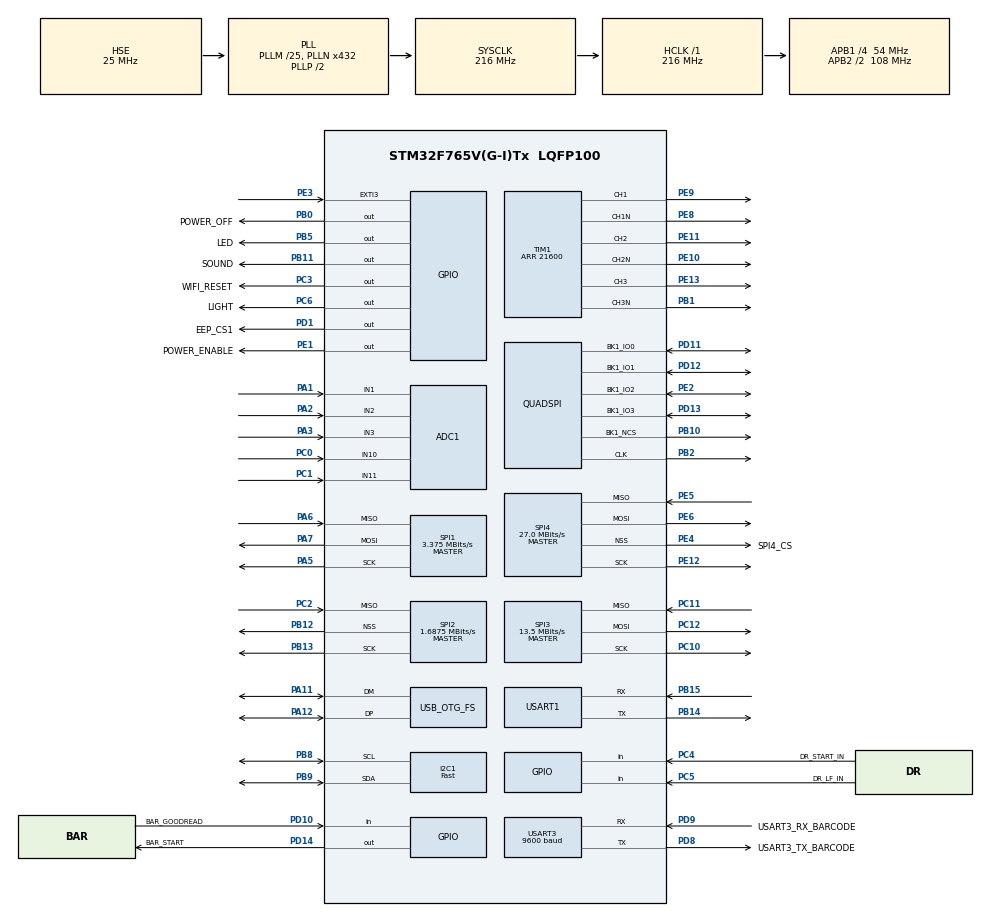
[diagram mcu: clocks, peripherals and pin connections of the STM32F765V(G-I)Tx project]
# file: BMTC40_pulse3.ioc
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ADC1.Channel-10\#ChannelRegularConversion=ADC_CHANNEL_10
ADC1.Channel-11\#ChannelRegularConversion=ADC_CHANNEL_11
ADC1.Channel-5\#ChannelRegularConversion=ADC_CHANNEL_1
ADC1.Channel-8\#ChannelRegularConversion=ADC_CHANNEL_2
ADC1.Channel-9\#ChannelRegularConversion=ADC_CHANNEL_3
ADC1.ClockPrescaler=ADC_CLOCK_SYNC_PCLK_DIV8
ADC1.ContinuousConvMode=DISABLE
ADC1.DMAContinuousRequests=ENABLE
ADC1.EOCSelection=ADC_EOC_SEQ_CONV
ADC1.NbrOfConversion=5
ADC1.NbrOfConversionFlag=1
ADC1.Rank-10\#ChannelRegularConversion=4
ADC1.Rank-11\#ChannelRegularConversion=5
ADC1.Rank-8\#ChannelRegularConversion=2
ADC1.Rank-9\#ChannelRegularConversion=3
ADC1.SamplingTime-10\#ChannelRegularConversion=ADC_SAMPLETIME_480CYCLES
ADC1.SamplingTime-11\#ChannelRegularConversion=ADC_SAMPLETIME_480CYCLES
ADC1.SamplingTime-5\#ChannelRegularConversion=ADC_SAMPLETIME_480CYCLES
ADC1.SamplingTime-8\#ChannelRegularConversion=ADC_SAMPLETIME_480CYCLES
ADC1.SamplingTime-9\#ChannelRegularConversion=ADC_SAMPLETIME_480CYCLES
ADC1.ScanConvMode=ADC_SCAN_ENABLE
ADC1.master=1
CORTEX_M7.ART_ACCELERATOR_ENABLE=0
CORTEX_M7.AccessPermission-Cortex_Memory_Protection_Unit_Region0_Settings=MPU_REGION_FULL_ACCESS
CORTEX_M7.BaseAddress-Cortex_Memory_Protection_Unit_Region0_Settings=0x20000000
CORTEX_M7.CPU_DCache=Enabled
CORTEX_M7.CPU_ICache=Enabled
CORTEX_M7.Enable-Cortex_Memory_Protection_Unit_Region0_Settings=MPU_REGION_ENABLE
CORTEX_M7.FlashInterface=AXI_Enabled
CORTEX_M7.IsBufferable-Cortex_Memory_Protection_Unit_Region0_Settings=MPU_ACCESS_NOT_BUFFERABLE
CORTEX_M7.IsShareable-Cortex_Memory_Protection_Unit_Region0_Settings=MPU_ACCESS_SHAREABLE
CORTEX_M7.MPU_Control=MPU_PRIVILEGED_DEFAULT
CORTEX_M7.PREFETCH_ENABLE=0
CORTEX_M7.Size-Cortex_Memory_Protection_Unit_Region0_Settings=MPU_REGION_SIZE_16KB
CORTEX_M7.TypeExtField-Cortex_Memory_Protection_Unit_Region0_Settings=MPU_TEX_LEVEL1
Dma.ADC1.2.Direction=DMA_PERIPH_TO_MEMORY
Dma.ADC1.2.FIFOMode=DMA_FIFOMODE_DISABLE
Dma.ADC1.2.Instance=DMA2_Stream4
Dma.ADC1.2.MemDataAlignment=DMA_MDATAALIGN_WORD
Dma.ADC1.2.MemInc=DMA_MINC_ENABLE
Dma.ADC1.2.Mode=DMA_NORMAL
Dma.ADC1.2.PeriphDataAlignment=DMA_PDATAALIGN_WORD
Dma.ADC1.2.PeriphInc=DMA_PINC_DISABLE
Dma.ADC1.2.Priority=DMA_PRIORITY_MEDIUM
Dma.I2C1_RX.0.Direction=DMA_PERIPH_TO_MEMORY
Dma.I2C1_RX.0.FIFOMode=DMA_FIFOMODE_DISABLE
Dma.I2C1_RX.0.Instance=DMA1_Stream0
Dma.I2C1_RX.0.MemDataAlignment=DMA_MDATAALIGN_BYTE
Dma.I2C1_RX.0.MemInc=DMA_MINC_ENABLE
Dma.I2C1_RX.0.Mode=DMA_NORMAL
Dma.I2C1_RX.0.PeriphDataAlignment=DMA_PDATAALIGN_BYTE
Dma.I2C1_RX.0.PeriphInc=DMA_PINC_DISABLE
Dma.I2C1_RX.0.Priority=DMA_PRIORITY_LOW
Dma.I2C1_TX.1.Direction=DMA_MEMORY_TO_PERIPH
Dma.I2C1_TX.1.FIFOMode=DMA_FIFOMODE_DISABLE
Dma.I2C1_TX.1.Instance=DMA1_Stream6
Dma.I2C1_TX.1.MemDataAlignment=DMA_MDATAALIGN_BYTE
Dma.I2C1_TX.1.MemInc=DMA_MINC_ENABLE
Dma.I2C1_TX.1.Mode=DMA_NORMAL
Dma.I2C1_TX.1.PeriphDataAlignment=DMA_PDATAALIGN_BYTE
Dma.I2C1_TX.1.PeriphInc=DMA_PINC_DISABLE
Dma.I2C1_TX.1.Priority=DMA_PRIORITY_LOW
Dma.Request0=I2C1_RX
Dma.Request1=I2C1_TX
Dma.Request10=SPI1_RX
Dma.Request11=SPI1_TX
Dma.Request2=ADC1
Dma.Request3=USART1_RX
Dma.Request4=USART1_TX
Dma.Request5=SPI4_RX
Dma.Request6=SPI4_TX
Dma.Request7=SPI2_RX
Dma.Request8=USART3_RX
Dma.Request9=USART3_TX
Dma.SPI1_RX.10.Direction=DMA_PERIPH_TO_MEMORY
Dma.SPI1_RX.10.FIFOMode=DMA_FIFOMODE_DISABLE
Dma.SPI1_RX.10.Instance=DMA2_Stream0
Dma.SPI1_RX.10.MemDataAlignment=DMA_MDATAALIGN_BYTE
Dma.SPI1_RX.10.MemInc=DMA_MINC_ENABLE
Dma.SPI1_RX.10.Mode=DMA_NORMAL
Dma.SPI1_RX.10.PeriphDataAlignment=DMA_PDATAALIGN_BYTE
Dma.SPI1_RX.10.PeriphInc=DMA_PINC_DISABLE
Dma.SPI1_RX.10.Priority=DMA_PRIORITY_VERY_HIGH
Dma.SPI1_TX.11.Direction=DMA_MEMORY_TO_PERIPH
Dma.SPI1_TX.11.FIFOMode=DMA_FIFOMODE_DISABLE
Dma.SPI1_TX.11.Instance=DMA2_Stream5
Dma.SPI1_TX.11.MemDataAlignment=DMA_MDATAALIGN_BYTE
Dma.SPI1_TX.11.MemInc=DMA_MINC_ENABLE
Dma.SPI1_TX.11.Mode=DMA_NORMAL
Dma.SPI1_TX.11.PeriphDataAlignment=DMA_PDATAALIGN_BYTE
Dma.SPI1_TX.11.PeriphInc=DMA_PINC_DISABLE
Dma.SPI1_TX.11.Priority=DMA_PRIORITY_VERY_HIGH
Dma.SPI2_RX.7.Direction=DMA_PERIPH_TO_MEMORY
Dma.SPI2_RX.7.FIFOMode=DMA_FIFOMODE_DISABLE
Dma.SPI2_RX.7.Instance=DMA1_Stream3
Dma.SPI2_RX.7.MemDataAlignment=DMA_MDATAALIGN_BYTE
Dma.SPI2_RX.7.MemInc=DMA_MINC_ENABLE
Dma.SPI2_RX.7.Mode=DMA_NORMAL
Dma.SPI2_RX.7.PeriphDataAlignment=DMA_PDATAALIGN_BYTE
Dma.SPI2_RX.7.PeriphInc=DMA_PINC_DISABLE
Dma.SPI2_RX.7.Priority=DMA_PRIORITY_HIGH
Dma.SPI4_RX.5.Direction=DMA_PERIPH_TO_MEMORY
Dma.SPI4_RX.5.FIFOMode=DMA_FIFOMODE_DISABLE
Dma.SPI4_RX.5.Instance=DMA2_Stream3
Dma.SPI4_RX.5.MemDataAlignment=DMA_MDATAALIGN_BYTE
Dma.SPI4_RX.5.MemInc=DMA_MINC_ENABLE
Dma.SPI4_RX.5.Mode=DMA_NORMAL
Dma.SPI4_RX.5.PeriphDataAlignment=DMA_PDATAALIGN_BYTE
Dma.SPI4_RX.5.PeriphInc=DMA_PINC_DISABLE
Dma.SPI4_RX.5.Priority=DMA_PRIORITY_LOW
Dma.SPI4_TX.6.Direction=DMA_MEMORY_TO_PERIPH
Dma.SPI4_TX.6.FIFOMode=DMA_FIFOMODE_DISABLE
Dma.SPI4_TX.6.Instance=DMA2_Stream1
Dma.SPI4_TX.6.MemDataAlignment=DMA_MDATAALIGN_BYTE
Dma.SPI4_TX.6.MemInc=DMA_MINC_ENABLE
Dma.SPI4_TX.6.Mode=DMA_NORMAL
Dma.SPI4_TX.6.PeriphDataAlignment=DMA_PDATAALIGN_BYTE
Dma.SPI4_TX.6.PeriphInc=DMA_PINC_DISABLE
Dma.SPI4_TX.6.Priority=DMA_PRIORITY_LOW
Dma.USART1_RX.3.Direction=DMA_PERIPH_TO_MEMORY
Dma.USART1_RX.3.FIFOMode=DMA_FIFOMODE_DISABLE
Dma.USART1_RX.3.Instance=DMA2_Stream2
Dma.USART1_RX.3.MemDataAlignment=DMA_MDATAALIGN_BYTE
Dma.USART1_RX.3.MemInc=DMA_MINC_ENABLE
Dma.USART1_RX.3.Mode=DMA_CIRCULAR
Dma.USART1_RX.3.PeriphDataAlignment=DMA_PDATAALIGN_BYTE
Dma.USART1_RX.3.PeriphInc=DMA_PINC_DISABLE
Dma.USART1_RX.3.Priority=DMA_PRIORITY_LOW
Dma.USART1_TX.4.Direction=DMA_MEMORY_TO_PERIPH
Dma.USART1_TX.4.FIFOMode=DMA_FIFOMODE_DISABLE
Dma.USART1_TX.4.Instance=DMA2_Stream7
Dma.USART1_TX.4.MemDataAlignment=DMA_MDATAALIGN_BYTE
Dma.USART1_TX.4.MemInc=DMA_MINC_ENABLE
Dma.USART1_TX.4.Mode=DMA_NORMAL
Dma.USART1_TX.4.PeriphDataAlignment=DMA_PDATAALIGN_BYTE
Dma.USART1_TX.4.PeriphInc=DMA_PINC_DISABLE
Dma.USART1_TX.4.Priority=DMA_PRIORITY_LOW
Dma.USART3_RX.8.Direction=DMA_PERIPH_TO_MEMORY
Dma.USART3_RX.8.FIFOMode=DMA_FIFOMODE_DISABLE
Dma.USART3_RX.8.Instance=DMA1_Stream1
Dma.USART3_RX.8.MemDataAlignment=DMA_MDATAALIGN_BYTE
Dma.USART3_RX.8.MemInc=DMA_MINC_ENABLE
Dma.USART3_RX.8.Mode=DMA_CIRCULAR
Dma.USART3_RX.8.PeriphDataAlignment=DMA_PDATAALIGN_BYTE
Dma.USART3_RX.8.PeriphInc=DMA_PINC_DISABLE
Dma.USART3_RX.8.Priority=DMA_PRIORITY_LOW
Dma.USART3_TX.9.Direction=DMA_MEMORY_TO_PERIPH
Dma.USART3_TX.9.FIFOMode=DMA_FIFOMODE_DISABLE
Dma.USART3_TX.9.Instance=DMA1_Stream4
Dma.USART3_TX.9.MemDataAlignment=DMA_MDATAALIGN_BYTE
Dma.USART3_TX.9.MemInc=DMA_MINC_ENABLE
Dma.USART3_TX.9.Mode=DMA_NORMAL
Dma.USART3_TX.9.PeriphDataAlignment=DMA_PDATAALIGN_BYTE
Dma.USART3_TX.9.PeriphInc=DMA_PINC_DISABLE
Dma.USART3_TX.9.Priority=DMA_PRIORITY_LOW
I2C1.GeneralCallMode=I2C_GENERALCALL_DISABLE
I2C1.I2C_Speed_Mode=I2C_Fast
I2C1.Timing=0x6000030D
IWDG.Prescaler=IWDG_PRESCALER_8
IWDG.Reload=2047
IWDG.Window=2047
Mcu.Family=STM32F7
Mcu.Name=STM32F765V(G-I)Tx
Mcu.Package=LQFP100
NVIC.DMA1_Stream0_IRQn=true\:4\:0\:true\:false\:true\:false\:true\:true
NVIC.DMA1_Stream1_IRQn=true\:4\:0\:true\:false\:true\:false\:true\:true
NVIC.DMA1_Stream3_IRQn=true\:2\:0\:false\:false\:true\:false\:true\:true
NVIC.DMA1_Stream4_IRQn=true\:4\:0\:true\:false\:true\:false\:true\:true
NVIC.DMA1_Stream6_IRQn=true\:4\:0\:true\:false\:true\:false\:true\:true
NVIC.DMA2_Stream0_IRQn=true\:0\:0\:true\:false\:true\:false\:true\:true
NVIC.DMA2_Stream1_IRQn=true\:4\:0\:true\:false\:true\:false\:true\:true
NVIC.DMA2_Stream2_IRQn=true\:4\:0\:true\:false\:true\:false\:true\:true
NVIC.DMA2_Stream3_IRQn=true\:4\:0\:true\:false\:true\:false\:true\:true
NVIC.DMA2_Stream4_IRQn=true\:4\:0\:false\:false\:true\:false\:true\:true
NVIC.DMA2_Stream5_IRQn=true\:0\:0\:false\:false\:true\:false\:true\:true
NVIC.DMA2_Stream7_IRQn=true\:4\:0\:true\:false\:true\:false\:true\:true
NVIC.EXTI3_IRQn=true\:4\:0\:true\:false\:true\:true\:true\:true
NVIC.I2C1_EV_IRQn=true\:4\:0\:true\:false\:true\:true\:true\:true
NVIC.OTG_FS_IRQn=true\:4\:0\:true\:false\:true\:true\:true\:true
NVIC.PriorityGroup=NVIC_PRIORITYGROUP_4
NVIC.QUADSPI_IRQn=true\:4\:0\:true\:false\:true\:true\:true\:true
NVIC.SPI2_IRQn=true\:2\:0\:true\:false\:true\:true\:true\:true
NVIC.TIM1_UP_TIM10_IRQn=true\:0\:0\:false\:false\:true\:true\:true\:true
NVIC.TIM8_TRG_COM_TIM14_IRQn=true\:1\:0\:true\:false\:true\:true\:true\:true
NVIC.TIM8_UP_TIM13_IRQn=true\:0\:0\:true\:false\:true\:true\:true\:true
NVIC.USART1_IRQn=true\:4\:0\:true\:false\:true\:true\:true\:true
PA0/WKUP.Mode=SYS_WakeUp0
PA0/WKUP.Signal=SYS_WKUP1
PA1.Signal=ADCx_IN1
PA11.GPIO_PuPd=GPIO_PULLDOWN
PA11.Mode=Device_Only
PA11.Signal=USB_OTG_FS_DM
PA12.GPIO_PuPd=GPIO_PULLDOWN
PA12.Mode=Device_Only
PA12.Signal=USB_OTG_FS_DP
PA13.Mode=JTAG_4_pins
PA13.Signal=SYS_JTMS-SWDIO
PA14.Mode=JTAG_4_pins
PA14.Signal=SYS_JTCK-SWCLK
PA15.Mode=JTAG_4_pins
PA15.Signal=SYS_JTDI
PA2.Signal=ADCx_IN2
PA3.Signal=ADCx_IN3
PA5.GPIO_PuPd=GPIO_PULLUP
PA5.Mode=Full_Duplex_Master
PA5.Signal=SPI1_SCK
PA6.Mode=Full_Duplex_Master
PA6.Signal=SPI1_MISO
PA7.Mode=Full_Duplex_Master
PA7.Signal=SPI1_MOSI
PB0.GPIO_Label=POWER_OFF
PB0.GPIO_PuPd=GPIO_PULLUP
PB0.PinState=GPIO_PIN_SET
PB0.Signal=GPIO_Output
PB1.GPIO_PuPd=GPIO_PULLDOWN
PB1.GPIO_Speed=GPIO_SPEED_FREQ_LOW
PB1.Mode=PWM Generation3 CH3 CH3N
PB1.Signal=TIM1_CH3N
PB10.GPIO_PuPd=GPIO_PULLDOWN
PB10.Mode=Single Bank 1
PB10.Signal=QUADSPI_BK1_NCS
PB11.GPIO_Label=SOUND
PB11.GPIO_PuPd=GPIO_PULLDOWN
PB11.Signal=GPIO_Output
PB12.GPIO_PuPd=GPIO_PULLUP
PB12.Mode=NSS_Signal_Hard_Output
PB12.Signal=SPI2_NSS
PB13.GPIO_PuPd=GPIO_PULLDOWN
PB13.Mode=RX_Only_Simplex_Unidirect_Master
PB13.Signal=SPI2_SCK
PB14.GPIO_PuPd=GPIO_PULLDOWN
PB14.Mode=Asynchronous
PB14.Signal=USART1_TX
PB15.GPIO_PuPd=GPIO_PULLDOWN
PB15.Mode=Asynchronous
PB15.Signal=USART1_RX
PB2.GPIO_PuPd=GPIO_PULLDOWN
PB2.Mode=Single Bank 1
PB2.Signal=QUADSPI_CLK
PB3.Mode=JTAG_4_pins
PB3.Signal=SYS_JTDO-SWO
PB5.GPIO_Label=LED
PB5.GPIO_PuPd=GPIO_PULLDOWN
PB5.Signal=GPIO_Output
PB8.GPIO_Pu=GPIO_PULLUP
PB8.Mode=I2C
PB8.Signal=I2C1_SCL
PB9.GPIO_Pu=GPIO_PULLUP
PB9.Mode=I2C
PB9.Signal=I2C1_SDA
PC0.Signal=ADCx_IN10
PC1.Signal=ADCx_IN11
PC10.GPIO_PuPd=GPIO_PULLDOWN
PC10.Mode=Full_Duplex_Master
PC10.Signal=SPI3_SCK
PC11.GPIO_PuPd=GPIO_PULLDOWN
PC11.Mode=Full_Duplex_Master
PC11.Signal=SPI3_MISO
PC12.GPIO_PuPd=GPIO_PULLDOWN
PC12.Mode=Full_Duplex_Master
PC12.Signal=SPI3_MOSI
PC14/OSC32_IN.Mode=LSE-External-Oscillator
PC14/OSC32_IN.Signal=RCC_OSC32_IN
PC15/OSC32_OUT.Mode=LSE-External-Oscillator
PC15/OSC32_OUT.Signal=RCC_OSC32_OUT
PC2.GPIO_PuPd=GPIO_PULLDOWN
PC2.Mode=RX_Only_Simplex_Unidirect_Master
PC2.Signal=SPI2_MISO
PC3.GPIO_Label=WIFI_RESET
PC3.GPIO_PuPd=GPIO_PULLDOWN
PC3.Signal=GPIO_Output
PC4.GPIO_Label=DR_START_IN
PC4.GPIO_PuPd=GPIO_PULLUP
PC4.Signal=GPIO_Input
PC5.GPIO_Label=DR_LF_IN
PC5.GPIO_PuPd=GPIO_PULLUP
PC5.Signal=GPIO_Input
PC6.GPIO_Label=LIGHT
PC6.GPIO_PuPd=GPIO_PULLDOWN
PC6.Signal=GPIO_Output
PD1.GPIO_Label=EEP_CS1
PD1.GPIO_ModeDefaultOutputPP=GPIO_MODE_OUTPUT_PP
PD1.GPIO_PuPd=GPIO_PULLUP
PD1.GPIO_Speed=GPIO_SPEED_FREQ_HIGH
PD1.PinState=GPIO_PIN_SET
PD1.Signal=GPIO_Output
PD10.GPIO_Label=BAR_GOODREAD
PD10.GPIO_PuPd=GPIO_PULLDOWN
PD10.Signal=GPIO_Input
PD11.GPIO_PuPd=GPIO_PULLDOWN
PD11.Mode=Single Bank 1
PD11.Signal=QUADSPI_BK1_IO0
PD12.GPIO_PuPd=GPIO_PULLDOWN
PD12.Mode=Single Bank 1
PD12.Signal=QUADSPI_BK1_IO1
PD13.GPIO_PuPd=GPIO_PULLDOWN
PD13.Mode=Single Bank 1
PD13.Signal=QUADSPI_BK1_IO3
PD14.GPIO_Label=BAR_START
PD14.GPIO_PuPd=GPIO_PULLDOWN
PD14.Signal=GPIO_Output
PD8.GPIO_Label=USART3_TX_BARCODE
PD8.GPIO_PuPd=GPIO_PULLDOWN
PD8.GPIO_Speed=GPIO_SPEED_FREQ_LOW
PD8.Mode=Asynchronous
PD8.Signal=USART3_TX
PD9.GPIO_Label=USART3_RX_BARCODE
PD9.GPIO_PuPd=GPIO_PULLDOWN
PD9.GPIO_Speed=GPIO_SPEED_FREQ_LOW
PD9.Mode=Asynchronous
PD9.Signal=USART3_RX
PE1.GPIO_Label=POWER_ENABLE
PE1.GPIO_PuPd=GPIO_PULLDOWN
PE1.PinState=GPIO_PIN_SET
PE1.Signal=GPIO_Output
PE10.GPIO_PuPd=GPIO_PULLDOWN
PE10.GPIO_Speed=GPIO_SPEED_FREQ_LOW
PE10.Mode=PWM Generation2 CH2 CH2N
PE10.Signal=TIM1_CH2N
PE11.GPIO_PuPd=GPIO_PULLDOWN
PE11.GPIO_Speed=GPIO_SPEED_FREQ_LOW
PE11.Signal=S_TIM1_CH2
PE12.GPIO_PuPd=GPIO_PULLDOWN
PE12.Mode=Full_Duplex_Master
PE12.Signal=SPI4_SCK
PE13.GPIO_PuPd=GPIO_PULLDOWN
PE13.GPIO_Speed=GPIO_SPEED_FREQ_LOW
PE13.Signal=S_TIM1_CH3
PE2.GPIO_PuPd=GPIO_PULLDOWN
PE2.Mode=Single Bank 1
PE2.Signal=QUADSPI_BK1_IO2
PE3.Signal=GPXTI3
PE4.GPIO_Label=SPI4_CS
PE4.Mode=NSS_Signal_Hard_Output
PE4.Signal=SPI4_NSS
PE5.GPIO_PuPd=GPIO_PULLDOWN
PE5.Mode=Full_Duplex_Master
PE5.Signal=SPI4_MISO
PE6.GPIO_PuPd=GPIO_PULLDOWN
PE6.Mode=Full_Duplex_Master
PE6.Signal=SPI4_MOSI
PE8.GPIO_PuPd=GPIO_PULLDOWN
PE8.GPIO_Speed=GPIO_SPEED_FREQ_LOW
PE8.Mode=PWM Generation1 CH1 CH1N
PE8.Signal=TIM1_CH1N
PE9.GPIO_PuPd=GPIO_PULLDOWN
PE9.GPIO_Speed=GPIO_SPEED_FREQ_LOW
PE9.Signal=S_TIM1_CH1
PH0/OSC_IN.Mode=HSE-External-Oscillator
PH0/OSC_IN.Signal=RCC_OSC_IN
PH1/OSC_OUT.Mode=HSE-External-Oscillator
PH1/OSC_OUT.Signal=RCC_OSC_OUT
ProjectManager.HeapSize=0x700
ProjectManager.StackSize=0x1000
ProjectManager.TargetToolchain=STM32CubeIDE
QUADSPI.ChipSelectHighTime=QSPI_CS_HIGH_TIME_5_CYCLE
QUADSPI.ClockPrescaler=2
QUADSPI.FlashSize=24 - 1
QUADSPI.SampleShifting=QSPI_SAMPLE_SHIFTING_HALFCYCLE
RCC.AHBFreq_Value=216000000
RCC.APB1CLKDivider=RCC_HCLK_DIV4
RCC.APB1Freq_Value=54000000
RCC.APB1TimFreq_Value=108000000
RCC.APB2CLKDivider=RCC_HCLK_DIV2
RCC.APB2Freq_Value=108000000
RCC.APB2TimFreq_Value=216000000
RCC.CortexFreq_Value=216000000
RCC.HCLKFreq_Value=216000000
RCC.HSE_VALUE=25000000
RCC.HSI_VALUE=16000000
RCC.PLLM=25
RCC.PLLN=432
RCC.PLLQ=9
RCC.RCC_MCO1Source=RCC_MCO1SOURCE_HSE
RCC.RTCClockSelection=RCC_RTCCLKSOURCE_LSE
RCC.SYSCLKFreq_VALUE=216000000
RCC.SYSCLKSource=RCC_SYSCLKSOURCE_PLLCLK
RCC.USBFreq_Value=48000000
RCC.VCOOutputFreq_Value=432000000
SH.ADCx_IN1.0=ADC1_IN1,IN1
SH.ADCx_IN10.0=ADC1_IN10,IN10
SH.ADCx_IN11.0=ADC1_IN11,IN11
SH.ADCx_IN2.0=ADC1_IN2,IN2
SH.ADCx_IN3.0=ADC1_IN3,IN3
SH.S_TIM1_CH1.0=TIM1_CH1,PWM Generation1 CH1 CH1N
SH.S_TIM1_CH2.0=TIM1_CH2,PWM Generation2 CH2 CH2N
SH.S_TIM1_CH3.0=TIM1_CH3,PWM Generation3 CH3 CH3N
SPI1.BaudRatePrescaler=SPI_BAUDRATEPRESCALER_32
SPI1.CLKPhase=SPI_PHASE_2EDGE
SPI1.CLKPolarity=SPI_POLARITY_HIGH
SPI1.CalculateBaudRate=3.375 MBits/s
SPI1.DataSize=SPI_DATASIZE_8BIT
SPI1.Direction=SPI_DIRECTION_2LINES
SPI1.Mode=SPI_MODE_MASTER
SPI1.VirtualType=VM_MASTER
SPI2.BaudRatePrescaler=SPI_BAUDRATEPRESCALER_32
SPI2.CalculateBaudRate=1.6875 MBits/s
SPI2.DataSize=SPI_DATASIZE_8BIT
SPI2.Direction=SPI_DIRECTION_2LINES_RXONLY
SPI2.Mode=SPI_MODE_MASTER
SPI2.NSSPMode=SPI_NSS_PULSE_DISABLE
SPI2.VirtualNSS=VM_NSSHARD
SPI2.VirtualType=VM_MASTER
SPI3.BaudRatePrescaler=SPI_BAUDRATEPRESCALER_4
SPI3.CalculateBaudRate=13.5 MBits/s
SPI3.DataSize=SPI_DATASIZE_8BIT
SPI3.Direction=SPI_DIRECTION_2LINES
SPI3.Mode=SPI_MODE_MASTER
SPI3.VirtualType=VM_MASTER
SPI4.BaudRatePrescaler=SPI_BAUDRATEPRESCALER_4
SPI4.CalculateBaudRate=27.0 MBits/s
SPI4.DataSize=SPI_DATASIZE_8BIT
SPI4.Direction=SPI_DIRECTION_2LINES
SPI4.Mode=SPI_MODE_MASTER
SPI4.VirtualNSS=VM_NSSHARD
SPI4.VirtualType=VM_MASTER
TIM1.AutoReloadPreload=TIM_AUTORELOAD_PRELOAD_DISABLE
TIM1.Channel-PWM\ Generation1\ CH1\ CH1N=TIM_CHANNEL_1
TIM1.Channel-PWM\ Generation2\ CH2\ CH2N=TIM_CHANNEL_2
TIM1.Channel-PWM\ Generation3\ CH3\ CH3N=TIM_CHANNEL_3
TIM1.CounterMode=TIM_COUNTERMODE_UP
TIM1.DeadTime=210
TIM1.OCFastMode_PWM-PWM\ Generation1\ CH1\ CH1N=TIM_OCFAST_ENABLE
TIM1.OCFastMode_PWM-PWM\ Generation2\ CH2\ CH2N=TIM_OCFAST_ENABLE
TIM1.OCFastMode_PWM-PWM\ Generation3\ CH3\ CH3N=TIM_OCFAST_ENABLE
TIM1.Period=21600
TIM1.RepetitionCounter=0
TIM13.AutoReloadPreload=TIM_AUTORELOAD_PRELOAD_ENABLE
TIM13.Period=10800
TIM14.AutoReloadPreload=TIM_AUTORELOAD_PRELOAD_ENABLE
TIM14.Period=10800/2
USART1.VirtualMode-Asynchronous=VM_ASYNC
USART3.BaudRate=9600
USART3.VirtualMode-Asynchronous=VM_ASYNC
USB_DEVICE.CLASS_NAME_FS=CDC
USB_DEVICE.MANUFACTURER_STRING-CDC_FS=HANTAS
USB_DEVICE.PRODUCT_STRING_CDC_FS=Virtual ComPort
USB_DEVICE.VirtualMode-CDC_FS=Cdc
USB_DEVICE.VirtualModeFS=Cdc_FS
USB_OTG_FS.VirtualMode=Device_Only
VP_IWDG_VS_IWDG.Mode=IWDG_Activate
VP_RTC_VS_RTC_Activate.Mode=RTC_Enabled
VP_RTC_VS_RTC_Calendar.Mode=RTC_Calendar
VP_TIM13_VS_ClockSourceINT.Mode=Enable_Timer
VP_TIM14_VS_ClockSourceINT.Mode=Enable_Timer
VP_USB_DEVICE_VS_USB_DEVICE_CDC_FS.Mode=CDC_FS
board=MDC_F765VG_BAT

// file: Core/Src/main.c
/* USER CODE BEGIN Header */
/**
  ******************************************************************************
  * @file           : main.c
  * @brief          : Main program body
  ******************************************************************************
  * @attention
  *
  * <h2><center>&copy; Copyright (c) 2020 STMicroelectronics.
  * All rights reserved.</center></h2>
  *
  * This software component is licensed by ST under Ultimate Liberty license
  * SLA0044, the "License"; You may not use this file except in compliance with
  * the License. You may obtain a copy of the License at:
  *                             www.st.com/SLA0044
  *
  ******************************************************************************
  */
/* USER CODE END Header */
#include "main.h"
#include "usb_device.h"

/* USER CODE BEGIN Includes */

#include "common.h"
#include "main_bg.h"
#include "ringBuffer.h"

#include "variable.h"
/* USER CODE END Includes */

ADC_HandleTypeDef hadc1;
DMA_HandleTypeDef hdma_adc1;

I2C_HandleTypeDef hi2c1;
DMA_HandleTypeDef hdma_i2c1_rx;
DMA_HandleTypeDef hdma_i2c1_tx;

IWDG_HandleTypeDef hiwdg;

QSPI_HandleTypeDef hqspi;

RTC_HandleTypeDef hrtc;

SPI_HandleTypeDef hspi1;
SPI_HandleTypeDef hspi2;
SPI_HandleTypeDef hspi3;
SPI_HandleTypeDef hspi4;
DMA_HandleTypeDef hdma_spi1_rx;
DMA_HandleTypeDef hdma_spi1_tx;
DMA_HandleTypeDef hdma_spi2_rx;
DMA_HandleTypeDef hdma_spi4_rx;
DMA_HandleTypeDef hdma_spi4_tx;

TIM_HandleTypeDef htim1;
TIM_HandleTypeDef htim13;
TIM_HandleTypeDef htim14;

UART_HandleTypeDef huart1;
UART_HandleTypeDef huart3;
DMA_HandleTypeDef hdma_usart1_rx;
DMA_HandleTypeDef hdma_usart1_tx;
DMA_HandleTypeDef hdma_usart3_rx;
DMA_HandleTypeDef hdma_usart3_tx;

void SystemClock_Config(void);
static void MPU_Config(void);
static void MX_GPIO_Init(void);
static void MX_DMA_Init(void);
static void MX_ADC1_Init(void);
static void MX_I2C1_Init(void);
static void MX_SPI3_Init(void);
static void MX_SPI4_Init(void);
static void MX_TIM1_Init(void);
static void MX_USART1_UART_Init(void);
static void MX_QUADSPI_Init(void);
static void MX_IWDG_Init(void);
static void MX_TIM13_Init(void);
static void MX_TIM14_Init(void);
static void MX_SPI2_Init(void);
static void MX_USART3_UART_Init(void);
static void MX_SPI1_Init(void);
static void MX_RTC_Init(void);

int main(void)
{

  /* MPU Configuration--------------------------------------------------------*/
  MPU_Config();

  /* Enable the CPU Cache */

  /* Enable I-Cache---------------------------------------------------------*/
  SCB_EnableICache();

  /* Enable D-Cache---------------------------------------------------------*/
  SCB_EnableDCache();

  /* MCU Configuration--------------------------------------------------------*/

  /* Reset of all peripherals, Initializes the Flash interface and the Systick. */
  HAL_Init();

  /* Configure the system clock */
  SystemClock_Config();

  /* USER CODE BEGIN SysInit */
  //  usbGpioReset();             // USB GPIO Init                             TODO: After MX_GPIO_Init();
  //  PowerWakeUpJudge();         // Sleep -> Switch wake up or IWDG wake up   TODO: After MX_ADC1_Init()
  /* USER CODE END SysInit */

  /* Initialize all configured peripherals */
  MX_GPIO_Init();
  MX_DMA_Init();
  MX_ADC1_Init();
  MX_I2C1_Init();
  MX_SPI3_Init();
  MX_SPI4_Init();
  MX_TIM1_Init();
  MX_USART1_UART_Init();
  MX_QUADSPI_Init();
  MX_IWDG_Init();
  MX_USB_DEVICE_Init();
  MX_TIM13_Init();
  MX_TIM14_Init();
  MX_SPI2_Init();
  MX_USART3_UART_Init();
  MX_SPI1_Init();
  MX_RTC_Init();
  /* USER CODE BEGIN 2 */

  HAL_GPIO_WritePin(POWER_ENABLE_GPIO_Port, POWER_ENABLE_Pin, GPIO_PIN_SET);
  HAL_GPIO_WritePin(POWER_OFF_GPIO_Port, POWER_OFF_Pin, GPIO_PIN_SET);
  HAL_Delay(600);

  main_init();
  HAL_Delay(100);

  printf("QB Start\n");

  /* USER CODE END 2 */

  /* Infinite loop */
  /* USER CODE BEGIN WHILE */
  while (1)
  {
    background();
    /* USER CODE END WHILE */

  }
}

void SystemClock_Config(void)
{
  RCC_OscInitTypeDef RCC_OscInitStruct = {0};
  RCC_ClkInitTypeDef RCC_ClkInitStruct = {0};

  /** Configure LSE Drive Capability
  */
  HAL_PWR_EnableBkUpAccess();
  __HAL_RCC_LSEDRIVE_CONFIG(RCC_LSEDRIVE_LOW);

  /** Configure the main internal regulator output voltage
  */
  __HAL_RCC_PWR_CLK_ENABLE();
  __HAL_PWR_VOLTAGESCALING_CONFIG(PWR_REGULATOR_VOLTAGE_SCALE1);

  /** Initializes the RCC Oscillators according to the specified parameters
  * in the RCC_OscInitTypeDef structure.
  */
  RCC_OscInitStruct.OscillatorType = RCC_OSCILLATORTYPE_LSI|RCC_OSCILLATORTYPE_HSE
                              |RCC_OSCILLATORTYPE_LSE;
  RCC_OscInitStruct.HSEState = RCC_HSE_ON;
  RCC_OscInitStruct.LSEState = RCC_LSE_ON;
  RCC_OscInitStruct.LSIState = RCC_LSI_ON;
  RCC_OscInitStruct.PLL.PLLState = RCC_PLL_ON;
  RCC_OscInitStruct.PLL.PLLSource = RCC_PLLSOURCE_HSE;
  RCC_OscInitStruct.PLL.PLLM = 25;
  RCC_OscInitStruct.PLL.PLLN = 432;
  RCC_OscInitStruct.PLL.PLLP = RCC_PLLP_DIV2;
  RCC_OscInitStruct.PLL.PLLQ = 9;
  RCC_OscInitStruct.PLL.PLLR = 2;
  if (HAL_RCC_OscConfig(&RCC_OscInitStruct) != HAL_OK)
  {
    Error_Handler();
  }

  /** Activate the Over-Drive mode
  */
  if (HAL_PWREx_EnableOverDrive() != HAL_OK)
  {
    Error_Handler();
  }

  /** Initializes the CPU, AHB and APB buses clocks
  */
  RCC_ClkInitStruct.ClockType = RCC_CLOCKTYPE_HCLK|RCC_CLOCKTYPE_SYSCLK
                              |RCC_CLOCKTYPE_PCLK1|RCC_CLOCKTYPE_PCLK2;
  RCC_ClkInitStruct.SYSCLKSource = RCC_SYSCLKSOURCE_PLLCLK;
  RCC_ClkInitStruct.AHBCLKDivider = RCC_SYSCLK_DIV1;
  RCC_ClkInitStruct.APB1CLKDivider = RCC_HCLK_DIV4;
  RCC_ClkInitStruct.APB2CLKDivider = RCC_HCLK_DIV2;

  if (HAL_RCC_ClockConfig(&RCC_ClkInitStruct, FLASH_LATENCY_7) != HAL_OK)
  {
    Error_Handler();
  }
}

static void MX_ADC1_Init(void)
{

  /* USER CODE BEGIN ADC1_Init 0 */
  // 1 / 108000000 * 4 * 480 = 17.7us
  /* USER CODE END ADC1_Init 0 */

  ADC_ChannelConfTypeDef sConfig = {0};

  /** Configure the global features of the ADC (Clock, Resolution, Data Alignment and number of conversion)
  */
  hadc1.Instance = ADC1;
  hadc1.Init.ClockPrescaler = ADC_CLOCK_SYNC_PCLK_DIV8;
  hadc1.Init.Resolution = ADC_RESOLUTION_12B;
  hadc1.Init.ScanConvMode = ADC_SCAN_ENABLE;
  hadc1.Init.ContinuousConvMode = DISABLE;
  hadc1.Init.DiscontinuousConvMode = DISABLE;
  hadc1.Init.ExternalTrigConvEdge = ADC_EXTERNALTRIGCONVEDGE_NONE;
  hadc1.Init.ExternalTrigConv = ADC_SOFTWARE_START;
  hadc1.Init.DataAlign = ADC_DATAALIGN_RIGHT;
  hadc1.Init.NbrOfConversion = 5;
  hadc1.Init.DMAContinuousRequests = ENABLE;
  hadc1.Init.EOCSelection = ADC_EOC_SEQ_CONV;
  if (HAL_ADC_Init(&hadc1) != HAL_OK)
  {
    Error_Handler();
  }

  /** Configure for the selected ADC regular channel its corresponding rank in the sequencer and its sample time.
  */
  sConfig.Channel = ADC_CHANNEL_1;
  sConfig.Rank = ADC_REGULAR_RANK_1;
  sConfig.SamplingTime = ADC_SAMPLETIME_480CYCLES;
  if (HAL_ADC_ConfigChannel(&hadc1, &sConfig) != HAL_OK)
  {
    Error_Handler();
  }

  /** Configure for the selected ADC regular channel its corresponding rank in the sequencer and its sample time.
  */
  sConfig.Channel = ADC_CHANNEL_2;
  sConfig.Rank = ADC_REGULAR_RANK_2;
  if (HAL_ADC_ConfigChannel(&hadc1, &sConfig) != HAL_OK)
  {
    Error_Handler();
  }

  /** Configure for the selected ADC regular channel its corresponding rank in the sequencer and its sample time.
  */
  sConfig.Channel = ADC_CHANNEL_3;
  sConfig.Rank = ADC_REGULAR_RANK_3;
  if (HAL_ADC_ConfigChannel(&hadc1, &sConfig) != HAL_OK)
  {
    Error_Handler();
  }

  /** Configure for the selected ADC regular channel its corresponding rank in the sequencer and its sample time.
  */
  sConfig.Channel = ADC_CHANNEL_10;
  sConfig.Rank = ADC_REGULAR_RANK_4;
  if (HAL_ADC_ConfigChannel(&hadc1, &sConfig) != HAL_OK)
  {
    Error_Handler();
  }

  /** Configure for the selected ADC regular channel its corresponding rank in the sequencer and its sample time.
  */
  sConfig.Channel = ADC_CHANNEL_11;
  sConfig.Rank = ADC_REGULAR_RANK_5;
  if (HAL_ADC_ConfigChannel(&hadc1, &sConfig) != HAL_OK)
  {
    Error_Handler();
  }

}

static void MX_I2C1_Init(void)
{

  hi2c1.Instance = I2C1;
  hi2c1.Init.Timing = 0x6000030D;
  hi2c1.Init.OwnAddress1 = 0;
  hi2c1.Init.AddressingMode = I2C_ADDRESSINGMODE_7BIT;
  hi2c1.Init.DualAddressMode = I2C_DUALADDRESS_DISABLE;
  hi2c1.Init.OwnAddress2 = 0;
  hi2c1.Init.OwnAddress2Masks = I2C_OA2_NOMASK;
  hi2c1.Init.GeneralCallMode = I2C_GENERALCALL_DISABLE;
  hi2c1.Init.NoStretchMode = I2C_NOSTRETCH_DISABLE;
  if (HAL_I2C_Init(&hi2c1) != HAL_OK)
  {
    Error_Handler();
  }

  /** Configure Analogue filter
  */
  if (HAL_I2CEx_ConfigAnalogFilter(&hi2c1, I2C_ANALOGFILTER_ENABLE) != HAL_OK)
  {
    Error_Handler();
  }

  /** Configure Digital filter
  */
  if (HAL_I2CEx_ConfigDigitalFilter(&hi2c1, 0) != HAL_OK)
  {
    Error_Handler();
  }

}

static void MX_IWDG_Init(void)
{

  hiwdg.Instance = IWDG;
  hiwdg.Init.Prescaler = IWDG_PRESCALER_8;
  hiwdg.Init.Window = 2047;
  hiwdg.Init.Reload = 2047;
  if (HAL_IWDG_Init(&hiwdg) != HAL_OK)
  {
    Error_Handler();
  }

}

static void MX_QUADSPI_Init(void)
{

  /* QUADSPI parameter configuration*/
  hqspi.Instance = QUADSPI;
  hqspi.Init.ClockPrescaler = 2;
  hqspi.Init.FifoThreshold = 1;
  hqspi.Init.SampleShifting = QSPI_SAMPLE_SHIFTING_HALFCYCLE;
  hqspi.Init.FlashSize = 24 - 1;
  hqspi.Init.ChipSelectHighTime = QSPI_CS_HIGH_TIME_5_CYCLE;
  hqspi.Init.ClockMode = QSPI_CLOCK_MODE_0;
  hqspi.Init.FlashID = QSPI_FLASH_ID_1;
  hqspi.Init.DualFlash = QSPI_DUALFLASH_DISABLE;
  if (HAL_QSPI_Init(&hqspi) != HAL_OK)
  {
    Error_Handler();
  }

}

static void MX_RTC_Init(void)
{

  RTC_TimeTypeDef sTime = {0};
  RTC_DateTypeDef sDate = {0};

  /** Initialize RTC Only
  */
  hrtc.Instance = RTC;
  hrtc.Init.HourFormat = RTC_HOURFORMAT_24;
  hrtc.Init.AsynchPrediv = 127;
  hrtc.Init.SynchPrediv = 255;
  hrtc.Init.OutPut = RTC_OUTPUT_DISABLE;
  hrtc.Init.OutPutPolarity = RTC_OUTPUT_POLARITY_HIGH;
  hrtc.Init.OutPutType = RTC_OUTPUT_TYPE_OPENDRAIN;
  if (HAL_RTC_Init(&hrtc) != HAL_OK)
  {
    Error_Handler();
  }

  /* USER CODE BEGIN Check_RTC_BKUP */

  // RTC TIME BACK UP
  if(HAL_RTCEx_BKUPRead(&hrtc, RTC_BKP_DR1) == 0x5A5B)
  {
    return;
  }

  HAL_RTCEx_BKUPWrite(&hrtc, RTC_BKP_DR1, 0x5A5B);

  /* USER CODE END Check_RTC_BKUP */

  /** Initialize RTC and set the Time and Date
  */
  sTime.Hours = 0x0;
  sTime.Minutes = 0x0;
  sTime.Seconds = 0x0;
  sTime.DayLightSaving = RTC_DAYLIGHTSAVING_NONE;
  sTime.StoreOperation = RTC_STOREOPERATION_RESET;
  if (HAL_RTC_SetTime(&hrtc, &sTime, RTC_FORMAT_BCD) != HAL_OK)
  {
    Error_Handler();
  }
  sDate.WeekDay = RTC_WEEKDAY_MONDAY;
  sDate.Month = RTC_MONTH_JANUARY;
  sDate.Date = 0x1;
  sDate.Year = 0x0;

  if (HAL_RTC_SetDate(&hrtc, &sDate, RTC_FORMAT_BCD) != HAL_OK)
  {
    Error_Handler();
  }

}

static void MX_SPI1_Init(void)
{

  /* SPI1 parameter configuration*/
  hspi1.Instance = SPI1;
  hspi1.Init.Mode = SPI_MODE_MASTER;
  hspi1.Init.Direction = SPI_DIRECTION_2LINES;
  hspi1.Init.DataSize = SPI_DATASIZE_8BIT;
  hspi1.Init.CLKPolarity = SPI_POLARITY_HIGH;
  hspi1.Init.CLKPhase = SPI_PHASE_2EDGE;
  hspi1.Init.NSS = SPI_NSS_SOFT;
  hspi1.Init.BaudRatePrescaler = SPI_BAUDRATEPRESCALER_32;
  hspi1.Init.FirstBit = SPI_FIRSTBIT_MSB;
  hspi1.Init.TIMode = SPI_TIMODE_DISABLE;
  hspi1.Init.CRCCalculation = SPI_CRCCALCULATION_DISABLE;
  hspi1.Init.CRCPolynomial = 7;
  hspi1.Init.CRCLength = SPI_CRC_LENGTH_DATASIZE;
  hspi1.Init.NSSPMode = SPI_NSS_PULSE_DISABLE;
  if (HAL_SPI_Init(&hspi1) != HAL_OK)
  {
    Error_Handler();
  }

}

static void MX_SPI2_Init(void)
{

  /* SPI2 parameter configuration*/
  hspi2.Instance = SPI2;
  hspi2.Init.Mode = SPI_MODE_MASTER;
  hspi2.Init.Direction = SPI_DIRECTION_2LINES_RXONLY;
  hspi2.Init.DataSize = SPI_DATASIZE_8BIT;
  hspi2.Init.CLKPolarity = SPI_POLARITY_LOW;
  hspi2.Init.CLKPhase = SPI_PHASE_1EDGE;
  hspi2.Init.NSS = SPI_NSS_HARD_OUTPUT;
  hspi2.Init.BaudRatePrescaler = SPI_BAUDRATEPRESCALER_32;
  hspi2.Init.FirstBit = SPI_FIRSTBIT_MSB;
  hspi2.Init.TIMode = SPI_TIMODE_DISABLE;
  hspi2.Init.CRCCalculation = SPI_CRCCALCULATION_DISABLE;
  hspi2.Init.CRCPolynomial = 7;
  hspi2.Init.CRCLength = SPI_CRC_LENGTH_DATASIZE;
  hspi2.Init.NSSPMode = SPI_NSS_PULSE_DISABLE;
  if (HAL_SPI_Init(&hspi2) != HAL_OK)
  {
    Error_Handler();
  }

}

static void MX_SPI3_Init(void)
{

  /* SPI3 parameter configuration*/
  hspi3.Instance = SPI3;
  hspi3.Init.Mode = SPI_MODE_MASTER;
  hspi3.Init.Direction = SPI_DIRECTION_2LINES;
  hspi3.Init.DataSize = SPI_DATASIZE_8BIT;
  hspi3.Init.CLKPolarity = SPI_POLARITY_LOW;
  hspi3.Init.CLKPhase = SPI_PHASE_1EDGE;
  hspi3.Init.NSS = SPI_NSS_SOFT;
  hspi3.Init.BaudRatePrescaler = SPI_BAUDRATEPRESCALER_4;
  hspi3.Init.FirstBit = SPI_FIRSTBIT_MSB;
  hspi3.Init.TIMode = SPI_TIMODE_DISABLE;
  hspi3.Init.CRCCalculation = SPI_CRCCALCULATION_DISABLE;
  hspi3.Init.CRCPolynomial = 7;
  hspi3.Init.CRCLength = SPI_CRC_LENGTH_DATASIZE;
  hspi3.Init.NSSPMode = SPI_NSS_PULSE_ENABLE;
  if (HAL_SPI_Init(&hspi3) != HAL_OK)
  {
    Error_Handler();
  }

}

static void MX_SPI4_Init(void)
{

  /* SPI4 parameter configuration*/
  hspi4.Instance = SPI4;
  hspi4.Init.Mode = SPI_MODE_MASTER;
  hspi4.Init.Direction = SPI_DIRECTION_2LINES;
  hspi4.Init.DataSize = SPI_DATASIZE_8BIT;
  hspi4.Init.CLKPolarity = SPI_POLARITY_LOW;
  hspi4.Init.CLKPhase = SPI_PHASE_1EDGE;
  hspi4.Init.NSS = SPI_NSS_HARD_OUTPUT;
  hspi4.Init.BaudRatePrescaler = SPI_BAUDRATEPRESCALER_4;
  hspi4.Init.FirstBit = SPI_FIRSTBIT_MSB;
  hspi4.Init.TIMode = SPI_TIMODE_DISABLE;
  hspi4.Init.CRCCalculation = SPI_CRCCALCULATION_DISABLE;
  hspi4.Init.CRCPolynomial = 7;
  hspi4.Init.CRCLength = SPI_CRC_LENGTH_DATASIZE;
  hspi4.Init.NSSPMode = SPI_NSS_PULSE_ENABLE;
  if (HAL_SPI_Init(&hspi4) != HAL_OK)
  {
    Error_Handler();
  }

}

static void MX_TIM1_Init(void)
{

  TIM_MasterConfigTypeDef sMasterConfig = {0};
  TIM_OC_InitTypeDef sConfigOC = {0};
  TIM_BreakDeadTimeConfigTypeDef sBreakDeadTimeConfig = {0};

  htim1.Instance = TIM1;
  htim1.Init.Prescaler = 0;
  htim1.Init.CounterMode = TIM_COUNTERMODE_UP;
  htim1.Init.Period = 21600;
  htim1.Init.ClockDivision = TIM_CLOCKDIVISION_DIV1;
  htim1.Init.RepetitionCounter = 0;
  htim1.Init.AutoReloadPreload = TIM_AUTORELOAD_PRELOAD_DISABLE;
  if (HAL_TIM_PWM_Init(&htim1) != HAL_OK)
  {
    Error_Handler();
  }
  sMasterConfig.MasterOutputTrigger = TIM_TRGO_RESET;
  sMasterConfig.MasterOutputTrigger2 = TIM_TRGO2_RESET;
  sMasterConfig.MasterSlaveMode = TIM_MASTERSLAVEMODE_DISABLE;
  if (HAL_TIMEx_MasterConfigSynchronization(&htim1, &sMasterConfig) != HAL_OK)
  {
    Error_Handler();
  }
  sConfigOC.OCMode = TIM_OCMODE_PWM1;
  sConfigOC.Pulse = 0;
  sConfigOC.OCPolarity = TIM_OCPOLARITY_HIGH;
  sConfigOC.OCNPolarity = TIM_OCNPOLARITY_HIGH;
  sConfigOC.OCFastMode = TIM_OCFAST_ENABLE;
  sConfigOC.OCIdleState = TIM_OCIDLESTATE_RESET;
  sConfigOC.OCNIdleState = TIM_OCNIDLESTATE_RESET;
  if (HAL_TIM_PWM_ConfigChannel(&htim1, &sConfigOC, TIM_CHANNEL_1) != HAL_OK)
  {
    Error_Handler();
  }
  if (HAL_TIM_PWM_ConfigChannel(&htim1, &sConfigOC, TIM_CHANNEL_2) != HAL_OK)
  {
    Error_Handler();
  }
  if (HAL_TIM_PWM_ConfigChannel(&htim1, &sConfigOC, TIM_CHANNEL_3) != HAL_OK)
  {
    Error_Handler();
  }
  sBreakDeadTimeConfig.OffStateRunMode = TIM_OSSR_DISABLE;
  sBreakDeadTimeConfig.OffStateIDLEMode = TIM_OSSI_DISABLE;
  sBreakDeadTimeConfig.LockLevel = TIM_LOCKLEVEL_OFF;
  sBreakDeadTimeConfig.DeadTime = 210;
  sBreakDeadTimeConfig.BreakState = TIM_BREAK_DISABLE;
  sBreakDeadTimeConfig.BreakPolarity = TIM_BREAKPOLARITY_HIGH;
  sBreakDeadTimeConfig.BreakFilter = 0;
  sBreakDeadTimeConfig.Break2State = TIM_BREAK2_DISABLE;
  sBreakDeadTimeConfig.Break2Polarity = TIM_BREAK2POLARITY_HIGH;
  sBreakDeadTimeConfig.Break2Filter = 0;
  sBreakDeadTimeConfig.AutomaticOutput = TIM_AUTOMATICOUTPUT_DISABLE;
  if (HAL_TIMEx_ConfigBreakDeadTime(&htim1, &sBreakDeadTimeConfig) != HAL_OK)
  {
    Error_Handler();
  }
  HAL_TIM_MspPostInit(&htim1);

}

static void MX_TIM13_Init(void)
{

  /* USER CODE BEGIN TIM13_Init 0 */
  // 10800 : 100us
  /* USER CODE END TIM13_Init 0 */

  htim13.Instance = TIM13;
  htim13.Init.Prescaler = 0;
  htim13.Init.CounterMode = TIM_COUNTERMODE_UP;
  htim13.Init.Period = 10800;
  htim13.Init.ClockDivision = TIM_CLOCKDIVISION_DIV1;
  htim13.Init.AutoReloadPreload = TIM_AUTORELOAD_PRELOAD_ENABLE;
  if (HAL_TIM_Base_Init(&htim13) != HAL_OK)
  {
    Error_Handler();
  }

}

static void MX_TIM14_Init(void)
{

  htim14.Instance = TIM14;
  htim14.Init.Prescaler = 0;
  htim14.Init.CounterMode = TIM_COUNTERMODE_UP;
  htim14.Init.Period = 10800/2;
  htim14.Init.ClockDivision = TIM_CLOCKDIVISION_DIV1;
  htim14.Init.AutoReloadPreload = TIM_AUTORELOAD_PRELOAD_ENABLE;
  if (HAL_TIM_Base_Init(&htim14) != HAL_OK)
  {
    Error_Handler();
  }

}

static void MX_USART1_UART_Init(void)
{

  huart1.Instance = USART1;
  huart1.Init.BaudRate = 115200;
  huart1.Init.WordLength = UART_WORDLENGTH_8B;
  huart1.Init.StopBits = UART_STOPBITS_1;
  huart1.Init.Parity = UART_PARITY_NONE;
  huart1.Init.Mode = UART_MODE_TX_RX;
  huart1.Init.HwFlowCtl = UART_HWCONTROL_NONE;
  huart1.Init.OverSampling = UART_OVERSAMPLING_16;
  huart1.Init.OneBitSampling = UART_ONE_BIT_SAMPLE_DISABLE;
  huart1.AdvancedInit.AdvFeatureInit = UART_ADVFEATURE_NO_INIT;
  if (HAL_UART_Init(&huart1) != HAL_OK)
  {
    Error_Handler();
  }

}

static void MX_USART3_UART_Init(void)
{

  huart3.Instance = USART3;
  huart3.Init.BaudRate = 9600;
  huart3.Init.WordLength = UART_WORDLENGTH_8B;
  huart3.Init.StopBits = UART_STOPBITS_1;
  huart3.Init.Parity = UART_PARITY_NONE;
  huart3.Init.Mode = UART_MODE_TX_RX;
  huart3.Init.HwFlowCtl = UART_HWCONTROL_NONE;
  huart3.Init.OverSampling = UART_OVERSAMPLING_16;
  huart3.Init.OneBitSampling = UART_ONE_BIT_SAMPLE_DISABLE;
  huart3.AdvancedInit.AdvFeatureInit = UART_ADVFEATURE_NO_INIT;
  if (HAL_UART_Init(&huart3) != HAL_OK)
  {
    Error_Handler();
  }

}

static void MX_DMA_Init(void)
{

  /* DMA controller clock enable */
  __HAL_RCC_DMA1_CLK_ENABLE();
  __HAL_RCC_DMA2_CLK_ENABLE();

  /* DMA interrupt init */
  /* DMA1_Stream0_IRQn interrupt configuration */
  HAL_NVIC_SetPriority(DMA1_Stream0_IRQn, 4, 0);
  HAL_NVIC_EnableIRQ(DMA1_Stream0_IRQn);
  /* DMA1_Stream1_IRQn interrupt configuration */
  HAL_NVIC_SetPriority(DMA1_Stream1_IRQn, 4, 0);
  HAL_NVIC_EnableIRQ(DMA1_Stream1_IRQn);
  /* DMA1_Stream3_IRQn interrupt configuration */
  HAL_NVIC_SetPriority(DMA1_Stream3_IRQn, 2, 0);
  HAL_NVIC_EnableIRQ(DMA1_Stream3_IRQn);
  /* DMA1_Stream4_IRQn interrupt configuration */
  HAL_NVIC_SetPriority(DMA1_Stream4_IRQn, 4, 0);
  HAL_NVIC_EnableIRQ(DMA1_Stream4_IRQn);
  /* DMA1_Stream6_IRQn interrupt configuration */
  HAL_NVIC_SetPriority(DMA1_Stream6_IRQn, 4, 0);
  HAL_NVIC_EnableIRQ(DMA1_Stream6_IRQn);
  /* DMA2_Stream0_IRQn interrupt configuration */
  HAL_NVIC_SetPriority(DMA2_Stream0_IRQn, 0, 0);
  HAL_NVIC_EnableIRQ(DMA2_Stream0_IRQn);
  /* DMA2_Stream1_IRQn interrupt configuration */
  HAL_NVIC_SetPriority(DMA2_Stream1_IRQn, 4, 0);
  HAL_NVIC_EnableIRQ(DMA2_Stream1_IRQn);
  /* DMA2_Stream2_IRQn interrupt configuration */
  HAL_NVIC_SetPriority(DMA2_Stream2_IRQn, 4, 0);
  HAL_NVIC_EnableIRQ(DMA2_Stream2_IRQn);
  /* DMA2_Stream3_IRQn interrupt configuration */
  HAL_NVIC_SetPriority(DMA2_Stream3_IRQn, 4, 0);
  HAL_NVIC_EnableIRQ(DMA2_Stream3_IRQn);
  /* DMA2_Stream4_IRQn interrupt configuration */
  HAL_NVIC_SetPriority(DMA2_Stream4_IRQn, 4, 0);
  HAL_NVIC_EnableIRQ(DMA2_Stream4_IRQn);
  /* DMA2_Stream5_IRQn interrupt configuration */
  HAL_NVIC_SetPriority(DMA2_Stream5_IRQn, 0, 0);
  HAL_NVIC_EnableIRQ(DMA2_Stream5_IRQn);
  /* DMA2_Stream7_IRQn interrupt configuration */
  HAL_NVIC_SetPriority(DMA2_Stream7_IRQn, 4, 0);
  HAL_NVIC_EnableIRQ(DMA2_Stream7_IRQn);

}

static void MX_GPIO_Init(void)
{
  GPIO_InitTypeDef GPIO_InitStruct = {0};

  /* GPIO Ports Clock Enable */
  __HAL_RCC_GPIOE_CLK_ENABLE();
  __HAL_RCC_GPIOC_CLK_ENABLE();
  __HAL_RCC_GPIOH_CLK_ENABLE();
  __HAL_RCC_GPIOA_CLK_ENABLE();
  __HAL_RCC_GPIOB_CLK_ENABLE();
  __HAL_RCC_GPIOD_CLK_ENABLE();

  /*Configure GPIO pin Output Level */
  HAL_GPIO_WritePin(GPIOC, WIFI_RESET_Pin|LIGHT_Pin, GPIO_PIN_RESET);

  /*Configure GPIO pin Output Level */
  HAL_GPIO_WritePin(POWER_OFF_GPIO_Port, POWER_OFF_Pin, GPIO_PIN_SET);

  /*Configure GPIO pin Output Level */
  HAL_GPIO_WritePin(GPIOB, SOUND_Pin|LED_Pin, GPIO_PIN_RESET);

  /*Configure GPIO pin Output Level */
  HAL_GPIO_WritePin(BAR_START_GPIO_Port, BAR_START_Pin, GPIO_PIN_RESET);

  /*Configure GPIO pin Output Level */
  HAL_GPIO_WritePin(EEP_CS1_GPIO_Port, EEP_CS1_Pin, GPIO_PIN_SET);

  /*Configure GPIO pin Output Level */
  HAL_GPIO_WritePin(POWER_ENABLE_GPIO_Port, POWER_ENABLE_Pin, GPIO_PIN_SET);

  /*Configure GPIO pin : PE3 */
  GPIO_InitStruct.Pin = GPIO_PIN_3;
  GPIO_InitStruct.Mode = GPIO_MODE_IT_RISING;
  GPIO_InitStruct.Pull = GPIO_NOPULL;
  HAL_GPIO_Init(GPIOE, &GPIO_InitStruct);

  /*Configure GPIO pins : WIFI_RESET_Pin LIGHT_Pin */
  GPIO_InitStruct.Pin = WIFI_RESET_Pin|LIGHT_Pin;
  GPIO_InitStruct.Mode = GPIO_MODE_OUTPUT_PP;
  GPIO_InitStruct.Pull = GPIO_PULLDOWN;
  GPIO_InitStruct.Speed = GPIO_SPEED_FREQ_LOW;
  HAL_GPIO_Init(GPIOC, &GPIO_InitStruct);

  /*Configure GPIO pins : DR_START_IN_Pin DR_LF_IN_Pin */
  GPIO_InitStruct.Pin = DR_START_IN_Pin|DR_LF_IN_Pin;
  GPIO_InitStruct.Mode = GPIO_MODE_INPUT;
  GPIO_InitStruct.Pull = GPIO_PULLUP;
  HAL_GPIO_Init(GPIOC, &GPIO_InitStruct);

  /*Configure GPIO pin : POWER_OFF_Pin */
  GPIO_InitStruct.Pin = POWER_OFF_Pin;
  GPIO_InitStruct.Mode = GPIO_MODE_OUTPUT_PP;
  GPIO_InitStruct.Pull = GPIO_PULLUP;
  GPIO_InitStruct.Speed = GPIO_SPEED_FREQ_LOW;
  HAL_GPIO_Init(POWER_OFF_GPIO_Port, &GPIO_InitStruct);

  /*Configure GPIO pins : SOUND_Pin LED_Pin */
  GPIO_InitStruct.Pin = SOUND_Pin|LED_Pin;
  GPIO_InitStruct.Mode = GPIO_MODE_OUTPUT_PP;
  GPIO_InitStruct.Pull = GPIO_PULLDOWN;
  GPIO_InitStruct.Speed = GPIO_SPEED_FREQ_LOW;
  HAL_GPIO_Init(GPIOB, &GPIO_InitStruct);

  /*Configure GPIO pin : BAR_GOODREAD_Pin */
  GPIO_InitStruct.Pin = BAR_GOODREAD_Pin;
  GPIO_InitStruct.Mode = GPIO_MODE_INPUT;
  GPIO_InitStruct.Pull = GPIO_PULLDOWN;
  HAL_GPIO_Init(BAR_GOODREAD_GPIO_Port, &GPIO_InitStruct);

  /*Configure GPIO pin : BAR_START_Pin */
  GPIO_InitStruct.Pin = BAR_START_Pin;
  GPIO_InitStruct.Mode = GPIO_MODE_OUTPUT_PP;
  GPIO_InitStruct.Pull = GPIO_PULLDOWN;
  GPIO_InitStruct.Speed = GPIO_SPEED_FREQ_LOW;
  HAL_GPIO_Init(BAR_START_GPIO_Port, &GPIO_InitStruct);

  /*Configure GPIO pin : EEP_CS1_Pin */
  GPIO_InitStruct.Pin = EEP_CS1_Pin;
  GPIO_InitStruct.Mode = GPIO_MODE_OUTPUT_PP;
  GPIO_InitStruct.Pull = GPIO_PULLUP;
  GPIO_InitStruct.Speed = GPIO_SPEED_FREQ_HIGH;
  HAL_GPIO_Init(EEP_CS1_GPIO_Port, &GPIO_InitStruct);

  /*Configure GPIO pin : POWER_ENABLE_Pin */
  GPIO_InitStruct.Pin = POWER_ENABLE_Pin;
  GPIO_InitStruct.Mode = GPIO_MODE_OUTPUT_PP;
  GPIO_InitStruct.Pull = GPIO_PULLDOWN;
  GPIO_InitStruct.Speed = GPIO_SPEED_FREQ_LOW;
  HAL_GPIO_Init(POWER_ENABLE_GPIO_Port, &GPIO_InitStruct);

  /* EXTI interrupt init*/
  HAL_NVIC_SetPriority(EXTI3_IRQn, 4, 0);
  HAL_NVIC_EnableIRQ(EXTI3_IRQn);

}

 /* MPU Configuration */

void MPU_Config(void)
{
  MPU_Region_InitTypeDef MPU_InitStruct = {0};

  /* Disables the MPU */
  HAL_MPU_Disable();

  /** Initializes and configures the Region and the memory to be protected
  */
  MPU_InitStruct.Enable = MPU_REGION_ENABLE;
  MPU_InitStruct.Number = MPU_REGION_NUMBER0;
  MPU_InitStruct.BaseAddress = 0x20000000;
  MPU_InitStruct.Size = MPU_REGION_SIZE_16KB;
  MPU_InitStruct.SubRegionDisable = 0x0;
  MPU_InitStruct.TypeExtField = MPU_TEX_LEVEL1;
  MPU_InitStruct.AccessPermission = MPU_REGION_FULL_ACCESS;
  MPU_InitStruct.DisableExec = MPU_INSTRUCTION_ACCESS_ENABLE;
  MPU_InitStruct.IsShareable = MPU_ACCESS_SHAREABLE;
  MPU_InitStruct.IsCacheable = MPU_ACCESS_NOT_CACHEABLE;
  MPU_InitStruct.IsBufferable = MPU_ACCESS_NOT_BUFFERABLE;

  HAL_MPU_ConfigRegion(&MPU_InitStruct);
  /* Enables the MPU */
  HAL_MPU_Enable(MPU_PRIVILEGED_DEFAULT);

}

void Error_Handler(void)
{
}
